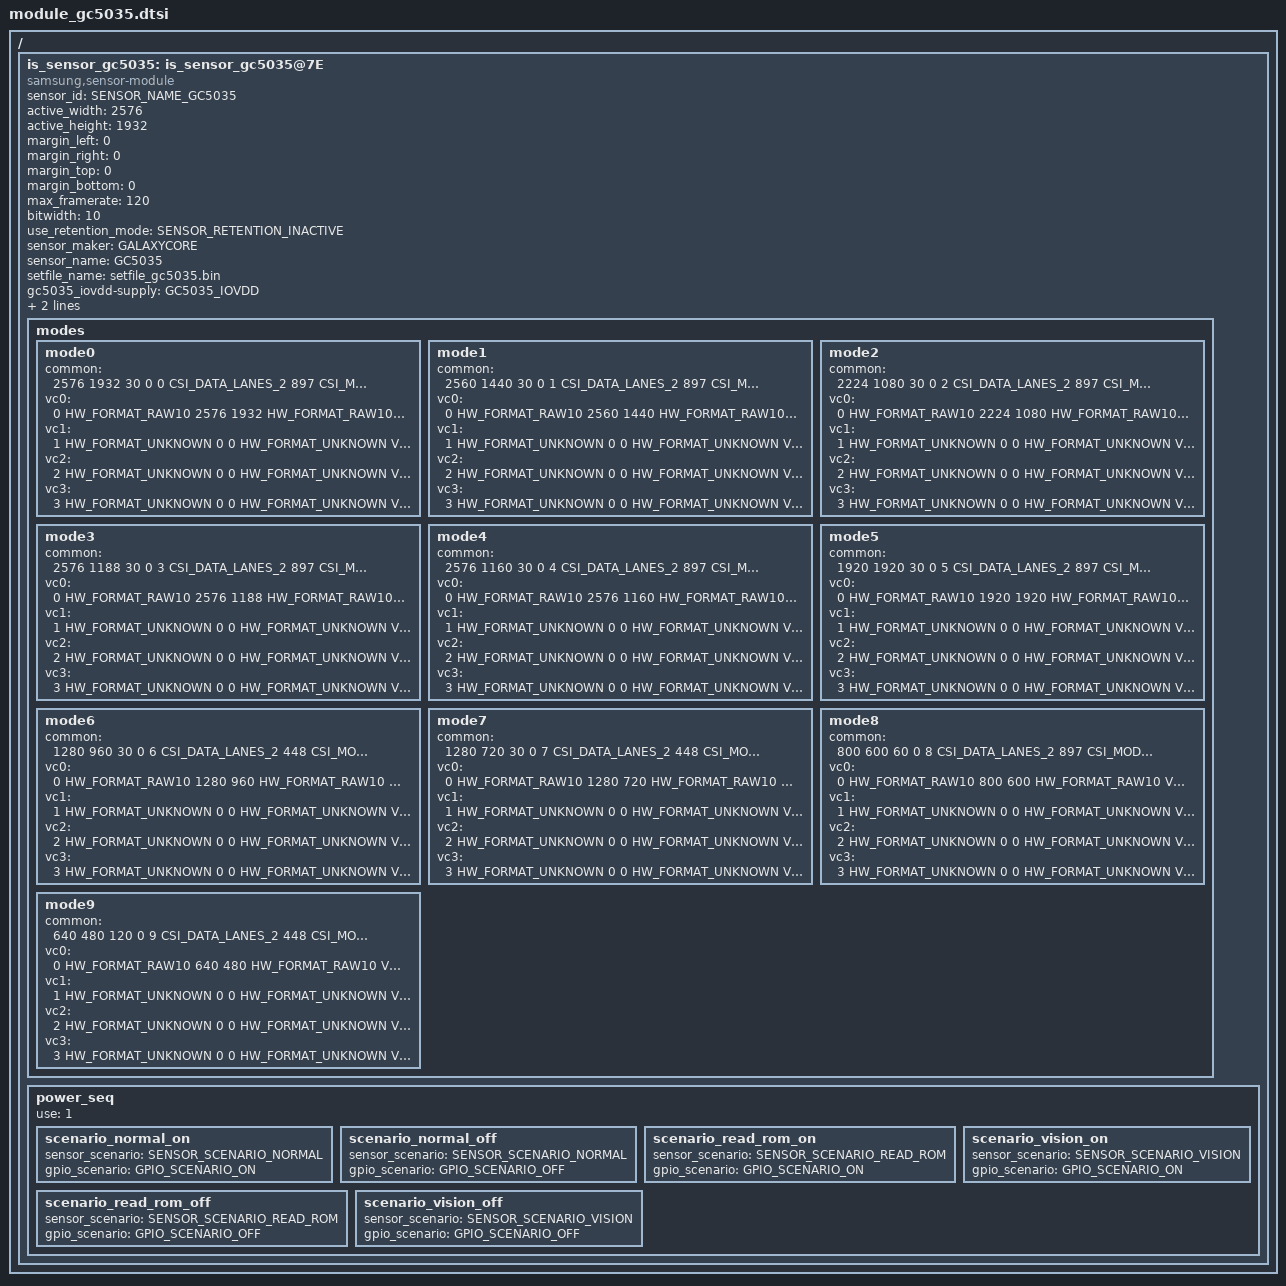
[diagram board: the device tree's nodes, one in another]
/*
 * SAMSUNG EXYNOSxxxx board camera device tree source
 *
 * Copyright (c) 2020 Samsung Electronics Co., Ltd.
 *        http://www.samsung.com
 *
 * This program is free software; you can redistribute it and/or modify
 * it under the terms of the GNU General Public License version 2 as
 * published by the Free Software Foundation.
 */

#include <dt-bindings/camera/exynos_is_dt.h>

#ifndef USE_VENDOR_PWR_PIN_NAME
#define GC5035_IOVDD	<>
#define GC5035_AVDD	<>
#define GC5035_DVDD	<>
#endif

/ {
	fragment@camera {
		target-path = "/";
		__overlay__ {
			is_sensor_gc5035: is_sensor_gc5035@7E {
				compatible = "samsung,sensor-module";

				/* common */
				sensor_id = <SENSOR_NAME_GC5035>;
				active_width = <2576>;
				active_height = <1932>;
				margin_left = <0>;
				margin_right = <0>;
				margin_top = <0>;
				margin_bottom = <0>;
				max_framerate = <120>;
				bitwidth = <10>;
				use_retention_mode = <SENSOR_RETENTION_INACTIVE>;
				sensor_maker = "GALAXYCORE";
				sensor_name = "GC5035";
				setfile_name = "setfile_gc5035.bin";

				gc5035_iovdd-supply = GC5035_IOVDD;
				gc5035_avdd-supply = GC5035_AVDD;
				gc5035_dvdd-supply = GC5035_DVDD;

				status = "okay";

/*
 * [Mode Information]
 *
 * Reference File : GC5035 MIPI data rate 897M official setfile V1.0.8.xlsx
 * Update Data    : 2019-12-10
 * Author         : sgtop9.choi
 *
 *  - Global setting
 *
 *  - Mode setting
 *  [ 0 ] 2576 x 1932(4:3)    @30,  MIPI lane: 2, MIPI data rate(Mbps/lane):  897, Mclk(Mhz): 26
 *  [ 1 ] 2560 x 1440(16:9)   @30,  MIPI lane: 2, MIPI data rate(Mbps/lane):  897, Mclk(Mhz): 26
 *  [ 2 ] 2224 x 1080(18.5:9) @30,  MIPI lane: 2, MIPI data rate(Mbps/lane):  897, Mclk(Mhz): 26
 *  [ 3 ] 2576 x 1188(19.5:9) @30,  MIPI lane: 2, MIPI data rate(Mbps/lane):  897, Mclk(Mhz): 26
 *  [ 4 ] 2576 x 1160(20:9)   @30,  MIPI lane: 2, MIPI data rate(Mbps/lane):  897, Mclk(Mhz): 26
 *  [ 5 ] 1920 x 1920(1:1)    @30,  MIPI lane: 2, MIPI data rate(Mbps/lane):  897, Mclk(Mhz): 26
 *  [ 6 ] 1280 x 960(4:3)     @30,  MIPI lane: 2, MIPI data rate(Mbps/lane):  897, Mclk(Mhz): 26
 *  [ 7 ] 1280 x 720(16:9)    @30,  MIPI lane: 2, MIPI data rate(Mbps/lane):  897, Mclk(Mhz): 26
 *  [ 8 ] 800 x 600(4:3)      @60,  MIPI lane: 2, MIPI data rate(Mbps/lane):  897, Mclk(Mhz): 26
 *  [ 9 ] 640 x 480(4:3)      @120,  MIPI lane: 2, MIPI data rate(Mbps/lane):  448, Mclk(Mhz): 26
 *
 */

				/* sensor modes */
				modes {
						/* common = <width, height, fps, settle, mode, lane, speed, interleave, lrte, pd_mode> */
						/* vcX = <map, hwformat, width, height, hwformat, type, width, height> */

					/* 0 : 2576x1932@30fps 4:3 */
					mode0 {
						common = <2576 1932 30 0 0 CSI_DATA_LANES_2 897 CSI_MODE_VC_ONLY LRTE_DISABLE PD_NONE EX_NONE>;
						vc0 = </* in */ 0 HW_FORMAT_RAW10 2576 1932	/* out */ HW_FORMAT_RAW10 VC_NOTHING 0 0>;
						vc1 = </* in */ 1 HW_FORMAT_UNKNOWN 0 0		/* out */ HW_FORMAT_UNKNOWN VC_NOTHING 0 0>;
						vc2 = </* in */ 2 HW_FORMAT_UNKNOWN 0 0		/* out */ HW_FORMAT_UNKNOWN VC_NOTHING 0 0>;
						vc3 = </* in */ 3 HW_FORMAT_UNKNOWN 0 0		/* out */ HW_FORMAT_UNKNOWN VC_NOTHING 0 0>;
					};
					/* 1 : 2560x1440@30fps 16:9 */
					mode1 {
						common = <2560 1440 30 0 1 CSI_DATA_LANES_2 897 CSI_MODE_VC_ONLY LRTE_DISABLE PD_NONE EX_NONE>;
						vc0 = </* in */ 0 HW_FORMAT_RAW10 2560 1440	/* out */ HW_FORMAT_RAW10 VC_NOTHING 0 0>;
						vc1 = </* in */ 1 HW_FORMAT_UNKNOWN 0 0		/* out */ HW_FORMAT_UNKNOWN VC_NOTHING 0 0>;
						vc2 = </* in */ 2 HW_FORMAT_UNKNOWN 0 0		/* out */ HW_FORMAT_UNKNOWN VC_NOTHING 0 0>;
						vc3 = </* in */ 3 HW_FORMAT_UNKNOWN 0 0		/* out */ HW_FORMAT_UNKNOWN VC_NOTHING 0 0>;
					};
					/* 2 : 2224x1080@30fps 18.5:9 */
					mode2 {
						common = <2224 1080 30 0 2 CSI_DATA_LANES_2 897 CSI_MODE_VC_ONLY LRTE_DISABLE PD_NONE EX_NONE>;
						vc0 = </* in */ 0 HW_FORMAT_RAW10 2224 1080	/* out */ HW_FORMAT_RAW10 VC_NOTHING 0 0>;
						vc1 = </* in */ 1 HW_FORMAT_UNKNOWN 0 0		/* out */ HW_FORMAT_UNKNOWN VC_NOTHING 0 0>;
						vc2 = </* in */ 2 HW_FORMAT_UNKNOWN 0 0		/* out */ HW_FORMAT_UNKNOWN VC_NOTHING 0 0>;
						vc3 = </* in */ 3 HW_FORMAT_UNKNOWN 0 0		/* out */ HW_FORMAT_UNKNOWN VC_NOTHING 0 0>;
					};
					/* 3 : 2576x1188@30fps 19.5:9 */
					mode3 {
						common = <2576 1188 30 0 3 CSI_DATA_LANES_2 897 CSI_MODE_VC_ONLY LRTE_DISABLE PD_NONE EX_NONE>;
						vc0 = </* in */ 0 HW_FORMAT_RAW10 2576 1188	/* out */ HW_FORMAT_RAW10 VC_NOTHING 0 0>;
						vc1 = </* in */ 1 HW_FORMAT_UNKNOWN 0 0		/* out */ HW_FORMAT_UNKNOWN VC_NOTHING 0 0>;
						vc2 = </* in */ 2 HW_FORMAT_UNKNOWN 0 0		/* out */ HW_FORMAT_UNKNOWN VC_NOTHING 0 0>;
						vc3 = </* in */ 3 HW_FORMAT_UNKNOWN 0 0		/* out */ HW_FORMAT_UNKNOWN VC_NOTHING 0 0>;
					};
					/* 4 : 2576x1160@30fps 20:9 */
					mode4 {
						common = <2576 1160 30 0 4 CSI_DATA_LANES_2 897 CSI_MODE_VC_ONLY LRTE_DISABLE PD_NONE EX_NONE>;
						vc0 = </* in */ 0 HW_FORMAT_RAW10 2576 1160	/* out */ HW_FORMAT_RAW10 VC_NOTHING 0 0>;
						vc1 = </* in */ 1 HW_FORMAT_UNKNOWN 0 0		/* out */ HW_FORMAT_UNKNOWN VC_NOTHING 0 0>;
						vc2 = </* in */ 2 HW_FORMAT_UNKNOWN 0 0		/* out */ HW_FORMAT_UNKNOWN VC_NOTHING 0 0>;
						vc3 = </* in */ 3 HW_FORMAT_UNKNOWN 0 0		/* out */ HW_FORMAT_UNKNOWN VC_NOTHING 0 0>;
					};
					/* 5 : 1920x1920@30fps 1:1 */
					mode5 {
						common = <1920 1920 30 0 5 CSI_DATA_LANES_2 897 CSI_MODE_VC_ONLY LRTE_DISABLE PD_NONE EX_NONE>;
						vc0 = </* in */ 0 HW_FORMAT_RAW10 1920 1920	/* out */ HW_FORMAT_RAW10 VC_NOTHING 0 0>;
						vc1 = </* in */ 1 HW_FORMAT_UNKNOWN 0 0		/* out */ HW_FORMAT_UNKNOWN VC_NOTHING 0 0>;
						vc2 = </* in */ 2 HW_FORMAT_UNKNOWN 0 0		/* out */ HW_FORMAT_UNKNOWN VC_NOTHING 0 0>;
						vc3 = </* in */ 3 HW_FORMAT_UNKNOWN 0 0		/* out */ HW_FORMAT_UNKNOWN VC_NOTHING 0 0>;
					};
					/* 6 : 1280x960@30fps 4:3 */
					mode6 {
						common = <1280 960 30 0 6 CSI_DATA_LANES_2 448 CSI_MODE_VC_ONLY LRTE_DISABLE PD_NONE EX_NONE>;
						vc0 = </* in */ 0 HW_FORMAT_RAW10 1280 960	/* out */ HW_FORMAT_RAW10 VC_NOTHING 0 0>;
						vc1 = </* in */ 1 HW_FORMAT_UNKNOWN 0 0		/* out */ HW_FORMAT_UNKNOWN VC_NOTHING 0 0>;
						vc2 = </* in */ 2 HW_FORMAT_UNKNOWN 0 0		/* out */ HW_FORMAT_UNKNOWN VC_NOTHING 0 0>;
						vc3 = </* in */ 3 HW_FORMAT_UNKNOWN 0 0		/* out */ HW_FORMAT_UNKNOWN VC_NOTHING 0 0>;
					};
					/* 7 : 1280x720@30fps 16:9 */
					mode7 {
						common = <1280 720 30 0 7 CSI_DATA_LANES_2 448 CSI_MODE_VC_ONLY LRTE_DISABLE PD_NONE EX_NONE>;
						vc0 = </* in */ 0 HW_FORMAT_RAW10 1280 720	/* out */ HW_FORMAT_RAW10 VC_NOTHING 0 0>;
						vc1 = </* in */ 1 HW_FORMAT_UNKNOWN 0 0		/* out */ HW_FORMAT_UNKNOWN VC_NOTHING 0 0>;
						vc2 = </* in */ 2 HW_FORMAT_UNKNOWN 0 0		/* out */ HW_FORMAT_UNKNOWN VC_NOTHING 0 0>;
						vc3 = </* in */ 3 HW_FORMAT_UNKNOWN 0 0		/* out */ HW_FORMAT_UNKNOWN VC_NOTHING 0 0>;
					};
					/* 8 : 800x600@60fps 4:3 */
					mode8 {
						common = <800 600 60 0 8 CSI_DATA_LANES_2 897 CSI_MODE_VC_ONLY LRTE_DISABLE PD_NONE EX_NONE>;
						vc0 = </* in */ 0 HW_FORMAT_RAW10 800 600	/* out */ HW_FORMAT_RAW10 VC_NOTHING 0 0>;
						vc1 = </* in */ 1 HW_FORMAT_UNKNOWN 0 0		/* out */ HW_FORMAT_UNKNOWN VC_NOTHING 0 0>;
						vc2 = </* in */ 2 HW_FORMAT_UNKNOWN 0 0		/* out */ HW_FORMAT_UNKNOWN VC_NOTHING 0 0>;
						vc3 = </* in */ 3 HW_FORMAT_UNKNOWN 0 0		/* out */ HW_FORMAT_UNKNOWN VC_NOTHING 0 0>;
					};
					/* 9 : 640x480@120fps 4:3 */
					mode9 {
						common = <640 480 120 0 9 CSI_DATA_LANES_2 448 CSI_MODE_VC_ONLY LRTE_DISABLE PD_NONE EX_NONE>;
						vc0 = </* in */ 0 HW_FORMAT_RAW10 640 480	/* out */ HW_FORMAT_RAW10 VC_NOTHING 0 0>;
						vc1 = </* in */ 1 HW_FORMAT_UNKNOWN 0 0		/* out */ HW_FORMAT_UNKNOWN VC_NOTHING 0 0>;
						vc2 = </* in */ 2 HW_FORMAT_UNKNOWN 0 0		/* out */ HW_FORMAT_UNKNOWN VC_NOTHING 0 0>;
						vc3 = </* in */ 3 HW_FORMAT_UNKNOWN 0 0		/* out */ HW_FORMAT_UNKNOWN VC_NOTHING 0 0>;
					};
				};

				power_seq {
					use = <1>;
					scenario_normal_on {
						sensor_scenario = <SENSOR_SCENARIO_NORMAL>;
						gpio_scenario = <GPIO_SCENARIO_ON>;

						/* A start node number should be over the 10 for reserved number 0~9. */
						/* pname = "name"; pin = <act value dealy voltage>; gpio = <gpx# # 0x1>; */
					};

					scenario_normal_off {
						sensor_scenario = <SENSOR_SCENARIO_NORMAL>;
						gpio_scenario = <GPIO_SCENARIO_OFF>;

						/* A start node number should be over the 10 for reserved number 0~9. */
						/* pname = "name"; pin = <act value dealy voltage>; gpio = <gpx# # 0x1>; */
					};

					scenario_read_rom_on {
						sensor_scenario = <SENSOR_SCENARIO_READ_ROM>;
						gpio_scenario = <GPIO_SCENARIO_ON>;
					};

					scenario_read_rom_off {
						sensor_scenario = <SENSOR_SCENARIO_READ_ROM>;
						gpio_scenario = <GPIO_SCENARIO_OFF>;
					};

					scenario_vision_on {
						sensor_scenario = <SENSOR_SCENARIO_VISION>;
						gpio_scenario = <GPIO_SCENARIO_ON>;

						/* A start node number should be over the 10 for reserved number 0~9. */
						/* pname = "name"; 		pin = <act value dealy voltage>;	gpio = <gpx# # 0x1>; */
					};

					scenario_vision_off {
						sensor_scenario = <SENSOR_SCENARIO_VISION>;
						gpio_scenario = <GPIO_SCENARIO_OFF>;

						/* A start node number should be over the 10 for reserved number 0~9. */
						/* pname = "name"; 		pin = <act value dealy voltage>;	gpio = <gpx# # 0x1>; */
					};
				};
			};

		}; /* end of __overlay__ */
	}; /* end of fragment */
}; /* end of root */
